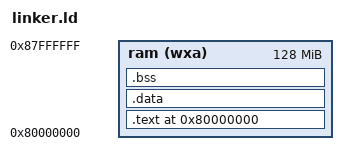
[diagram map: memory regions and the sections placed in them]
MEMORY
{
    ram (wxa) : ORIGIN = 0x80000000, LENGTH = 128M
}

SECTIONS
{
    . = 0x80000000;

    .text : {
        *(.text.entry)
        *(.text .text.*)
    } > ram

    /* The Global Pointer ($gp) usually points to the start of data + 0x800 */
    .data : {
        __global_pointer$ = . + 0x800;
        *(.data .data.*)
        *(.sdata .sdata.*)
    } > ram

    .bss : {
        __bss_start = .;
        *(.bss .bss.*)
        *(.sbss .sbss.*)
        *(COMMON)
        _end = .;
    } > ram
}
